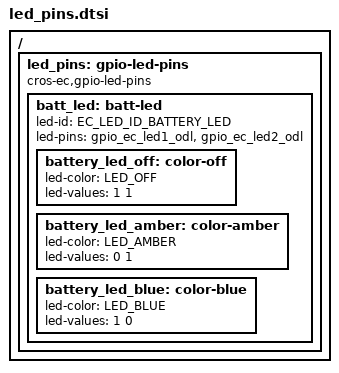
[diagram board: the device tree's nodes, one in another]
/* Copyright 2026 The ChromiumOS Authors
 * Use of this source code is governed by a BSD-style license that can be
 * found in the LICENSE file.
 */

/ {
	led_pins: gpio-led-pins {
		compatible = "cros-ec,gpio-led-pins";

		batt_led: batt-led {
			led-id = "EC_LED_ID_BATTERY_LED";
			led-pins = <&gpio_ec_led1_odl &gpio_ec_led2_odl>;
			battery_led_off: color-off {
				led-color = "LED_OFF";
				led-values = <1 1>;
			};

			battery_led_amber: color-amber {
				led-color = "LED_AMBER";
				led-values = <0 1>;
			};

			battery_led_blue: color-blue {
				led-color = "LED_BLUE";
				led-values = <1 0>;
			};
		};
	};
};
